AUTOSAR XML (schema 4-3-0)
package /BMW/Platform/Bs/SwcImplementations
  swc implementation Bs_Impl: behavior=Bs_IB
    code-descriptors:
      code Bs_Impl_Code: artifact-descriptors=autosar-engineering-object={short-label=Default, category=SWSRC}
package /BMW/Platform/Bs/SwComponentTypes
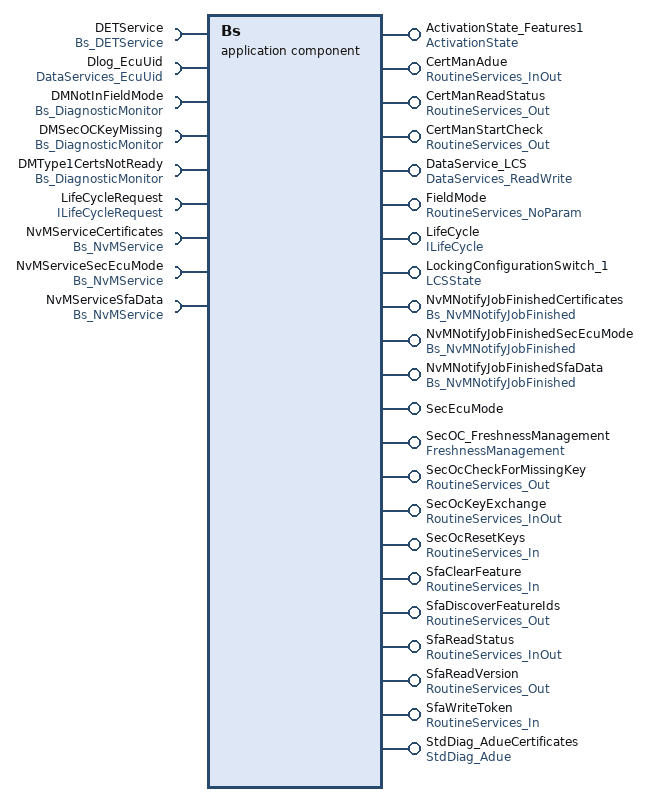
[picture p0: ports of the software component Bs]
  application sw component type Bs
    22 x provide port:
      ActivationState_Features1: nonqueued-sender-com-spec=data-element=IsActivated, provided-interface=ActivationState
      CertManAdue: server-com-spec{operation=Start, queue-length=1}, provided-interface=RoutineServices_InOut
      CertManReadStatus: server-com-spec{operation=Start, queue-length=1}, provided-interface=RoutineServices_Out
      CertManStartCheck: server-com-spec{operation=Start, queue-length=1}, provided-interface=RoutineServices_Out
      DataService_LCS: provided-interface=DataServices_ReadWrite
        provided-com-specs:
          operation=ConditionCheckRead, queue-length=1
          operation=ReadData, queue-length=1
          operation=ReadDataLength, queue-length=1
          operation=WriteData, queue-length=1
      FieldMode: server-com-spec{operation=Start, queue-length=1}, provided-interface=RoutineServices_NoParam
      LifeCycle: mode-switch-sender-com-spec{enhanced-mode-api=true, mode-group=Mode, queue-length=2}, provided-interface=ILifeCycle
      LockingConfigurationSwitch_1: nonqueued-sender-com-spec=data-element=value, provided-interface=LCSState
      NvMNotifyJobFinishedCertificates: server-com-spec{operation=JobFinished, queue-length=1}, provided-interface=Bs_NvMNotifyJobFinished
      NvMNotifyJobFinishedSecEcuMode: server-com-spec{operation=JobFinished, queue-length=1}, provided-interface=Bs_NvMNotifyJobFinished
      NvMNotifyJobFinishedSfaData: server-com-spec{operation=JobFinished, queue-length=1}, provided-interface=Bs_NvMNotifyJobFinished
      SecEcuMode: mode-switch-sender-com-spec{enhanced-mode-api=false, mode-group=Mode, queue-length=1}, provided-interface=SecEcuMode
      SecOC_FreshnessManagement: provided-interface=FreshnessManagement
        provided-com-specs:
          operation=GetRxFreshnessAuthData, queue-length=1
          operation=GetTxFreshnessTruncData, queue-length=1
          operation=SPduTxConfirmation, queue-length=1
      SecOcCheckForMissingKey: server-com-spec{operation=Start, queue-length=1}, provided-interface=RoutineServices_Out
      SecOcKeyExchange: server-com-spec{operation=Start, queue-length=1}, provided-interface=RoutineServices_InOut
      SecOcResetKeys: server-com-spec{operation=Start, queue-length=1}, provided-interface=RoutineServices_In
      SfaClearFeature: server-com-spec{operation=Start, queue-length=1}, provided-interface=RoutineServices_In
      SfaDiscoverFeatureIds: server-com-spec{operation=Start, queue-length=1}, provided-interface=RoutineServices_Out
      SfaReadStatus: server-com-spec{operation=Start, queue-length=1}, provided-interface=RoutineServices_InOut
      SfaReadVersion: server-com-spec{operation=Start, queue-length=1}, provided-interface=RoutineServices_Out
      SfaWriteToken: server-com-spec{operation=Start, queue-length=1}, provided-interface=RoutineServices_In
      StdDiag_AdueCertificates: provided-interface=StdDiag_Adue
        provided-com-specs:
          operation=CancelOperation, queue-length=1
          operation=Download, queue-length=1
          operation=DownloadPostprocess, queue-length=1
          operation=DownloadPreprocess, queue-length=1
          operation=RequestDownload, queue-length=1
          operation=RequestDownloadExit, queue-length=1
          operation=RequestUpload, queue-length=1
          operation=RequestUploadExit, queue-length=1
          operation=Upload, queue-length=1
          operation=UploadPostprocess, queue-length=1
          operation=UploadPreprocess, queue-length=1
    9 x require port:
      DETService: required-interface=Bs_DETService
      Dlog_EcuUid: required-interface=DataServices_EcuUid
      DMNotInFieldMode: required-interface=Bs_DiagnosticMonitor
      DMSecOCKeyMissing: required-interface=Bs_DiagnosticMonitor
      DMType1CertsNotReady: required-interface=Bs_DiagnosticMonitor
      LifeCycleRequest: nonqueued-receiver-com-spec{data-element=requestMode, filter=data-filter-type=ALWAYS, init-value=2}, required-interface=ILifeCycleRequest
      NvMServiceCertificates: required-interface=Bs_NvMService
      NvMServiceSecEcuMode: required-interface=Bs_NvMService
      NvMServiceSfaData: required-interface=Bs_NvMService
    behavior Bs_IB: data-type-mapping=BsTypeMappings, port-api-option{enable-take-address=true, error-handling=NO-TRANSFORMER-ERROR-HANDLING, indirect-api=false, port=ActivationState_Features1}
      11 x operation invoked event:
        oie_StdDiag_AdueCertificates_CancelOperation: start-on-event=Bs_AdueCertificatesCancel, operation=StdDiag_AdueCertificates.CancelOperation
        oie_StdDiag_AdueCertificates_Download: start-on-event=Bs_AdueCertificatesDownload, operation=StdDiag_AdueCertificates.Download
        oie_StdDiag_AdueCertificates_DownloadPostprocess: start-on-event=Bs_AdueCertificatesDownloadPostprocess, operation=StdDiag_AdueCertificates.DownloadPostprocess
        oie_StdDiag_AdueCertificates_DownloadPreprocess: start-on-event=Bs_AdueCertificatesDownloadPreprocess, operation=StdDiag_AdueCertificates.DownloadPreprocess
        oie_StdDiag_AdueCertificates_ReqeuestDownload: start-on-event=Bs_AdueCertificatesReqeuestDownload, operation=StdDiag_AdueCertificates.RequestDownload
        oie_StdDiag_AdueCertificates_RequestDownloadExit: start-on-event=Bs_AdueCertificatesRequestDownloadExit, operation=StdDiag_AdueCertificates.RequestDownloadExit
        oie_StdDiag_AdueCertificates_RequestUpload: start-on-event=Bs_AdueCertificatesRequestUpload, operation=StdDiag_AdueCertificates.RequestUpload
        oie_StdDiag_AdueCertificates_RequestUploadExit: start-on-event=Bs_AdueCertificatesRequestUploadExit, operation=StdDiag_AdueCertificates.RequestUploadExit
        oie_StdDiag_AdueCertificates_Upload: start-on-event=Bs_AdueCertificatesUpload, operation=StdDiag_AdueCertificates.Upload
        oie_StdDiag_AdueCertificates_UploadPostprocess: start-on-event=Bs_AdueCertificatesUploadPostprocess, operation=StdDiag_AdueCertificates.UploadPostprocess
        oie_StdDiag_AdueCertificates_UploadPreprocess: start-on-event=Bs_AdueCertificatesUploadPreprocess, operation=StdDiag_AdueCertificates.UploadPreprocess
      data received event dre_LifeCycleRequest: start-on-event=Bs_LifeCycleModeRequest, data=LifeCycleRequest.requestMode
      22 x operation invoked event:
        oie_NvMNotifyJobFinishedCertificates_JobFinished: start-on-event=Bs_NvMNotifyJobFinishedCertificates, operation=NvMNotifyJobFinishedCertificates.JobFinished
        oie_NvMNotifyJobFinishedSecEcuMode_JobFinished: start-on-event=Bs_NvMNotifyJobFinishedSecEcuMode, operation=NvMNotifyJobFinishedSecEcuMode.JobFinished
        oie_NvMNotifyJobFinishedSfaData_JobFinished: start-on-event=Bs_NvMNotifyJobFinishedSfaData, operation=NvMNotifyJobFinishedSfaData.JobFinished
        oie_SecOC_FreshnessManagement_GetRxFreshnessAuthData: start-on-event=Bs_SecOCFMGetRxFreshnessAuthData, operation=SecOC_FreshnessManagement.GetRxFreshnessAuthData
        oie_SecOC_FreshnessManagement_GetTxFreshnessTruncData: start-on-event=Bs_SecOCFMGetTxFreshnessTruncData, operation=SecOC_FreshnessManagement.GetTxFreshnessTruncData
        oie_SecOC_FreshnessManagement_SPduTxConfirmation: start-on-event=Bs_SecOCFMSPduTxConfirmation, operation=SecOC_FreshnessManagement.SPduTxConfirmation
        oie_DataService_LCS_ConditionCheckRead: start-on-event=Bs_UDSConditionCheckReadLCS, operation=DataService_LCS.ConditionCheckRead
        oie_DataService_LCS_ReadData: start-on-event=Bs_UDSReadDataByIdentifierLCS, operation=DataService_LCS.ReadData
        oie_DataService_LCS_ReadDataLength: start-on-event=Bs_UDSReadDataLengthLCS, operation=DataService_LCS.ReadDataLength
        oie_CertManAdue_Start: start-on-event=Bs_UDSRoutineControlStartCertManAdue, operation=CertManAdue.Start
        oie_CertManReadStatus_Start: start-on-event=Bs_UDSRoutineControlStartCertManReadStatus, operation=CertManReadStatus.Start
        oie_CertManStartCheck_Start: start-on-event=Bs_UDSRoutineControlStartCertManStartCheck, operation=CertManStartCheck.Start
        oie_FieldMode_Start: start-on-event=Bs_UDSRoutineControlStartFieldMode, operation=FieldMode.Start
        oie_SecOcCheckForMissingKey_Start: start-on-event=Bs_UDSRoutineControlStartSecOcCheckForMissingKey, operation=SecOcCheckForMissingKey.Start
        oie_SecOcKeyExchange_Start: start-on-event=Bs_UDSRoutineControlStartSecOcKeyExchange, operation=SecOcKeyExchange.Start
        oie_SecOcResetKeys_Start: start-on-event=Bs_UDSRoutineControlStartSecOcResetKeys, operation=SecOcResetKeys.Start
        oie_SfaClearFeature_Start: start-on-event=Bs_UDSRoutineControlStartSfaClearFeature, operation=SfaClearFeature.Start
        oie_SfaDiscoverFeatureIds_Start: start-on-event=Bs_UDSRoutineControlStartSfaDiscoverFeatureIds, operation=SfaDiscoverFeatureIds.Start
        oie_SfaReadStatus_Start: start-on-event=Bs_UDSRoutineControlStartSfaReadStatus, operation=SfaReadStatus.Start
        oie_SfaReadVersion_Start: start-on-event=Bs_UDSRoutineControlStartSfaReadVersion, operation=SfaReadVersion.Start
        oie_SfaWriteToken_Start: start-on-event=Bs_UDSRoutineControlStartSfaWriteToken, operation=SfaWriteToken.Start
        oie_DataService_LCS_WriteData: start-on-event=Bs_UDSWriteDataByIdentifierLCS, operation=DataService_LCS.WriteData
      34 x runnable:
        Bs_AdueCertificatesCancel
        Bs_AdueCertificatesDownload
        Bs_AdueCertificatesDownloadPostprocess
        Bs_AdueCertificatesDownloadPreprocess
        Bs_AdueCertificatesReqeuestDownload: symbol=Bs_AdueCertificates_ReqeuestDownload
        Bs_AdueCertificatesRequestDownloadExit
        Bs_AdueCertificatesRequestUpload
        Bs_AdueCertificatesRequestUploadExit
        Bs_AdueCertificatesUpload
        Bs_AdueCertificatesUploadPostprocess
        Bs_AdueCertificatesUploadPreprocess
          sync call scp_ReportError: operation=DETService.ReportError, timeout=0
        Bs_LifeCycleModeRequest: mode-access-point=LifeCycle.Mode
          data-read-access:
            access dra_requestMode: accessed-variable=LifeCycleRequest.requestMode
          mode switch point msp_proto_Bs_LifeCycle_0: mode-group=LifeCycle.Mode
          mode switch point msp_proto_SecEcuModeGroup_0: mode-group=SecEcuMode.Mode
          sync call scp_GetErrorStatus: operation=NvMServiceSecEcuMode.GetErrorStatus, timeout=0
          sync call scp_SetEventStatus: operation=DMNotInFieldMode.SetEventStatus, timeout=0
        Bs_NvMNotifyJobFinishedCertificates
        Bs_NvMNotifyJobFinishedSecEcuMode
        Bs_NvMNotifyJobFinishedSfaData
          data-send-points:
            access dsp_IsActivated: accessed-variable=ActivationState_Features1.IsActivated
          mode switch point msp_Mode_0: mode-group=SecEcuMode.Mode
          sync call scp_SetRamBlockStatus: operation=NvMServiceSecEcuMode.SetRamBlockStatus, timeout=0
        Bs_SecOCFMGetRxFreshnessAuthData
        Bs_SecOCFMGetTxFreshnessTruncData
        Bs_SecOCFMSPduTxConfirmation
        Bs_UDSConditionCheckReadLCS
        Bs_UDSReadDataByIdentifierLCS
        Bs_UDSReadDataLengthLCS
        Bs_UDSRoutineControlStartCertManAdue
        Bs_UDSRoutineControlStartCertManReadStatus
        Bs_UDSRoutineControlStartCertManStartCheck
        Bs_UDSRoutineControlStartFieldMode
          mode switch point msp_proto_SecEcuModeGroup_1: mode-group=SecEcuMode.Mode
          sync call scp_WriteBlock: operation=NvMServiceSecEcuMode.WriteBlock, timeout=0
        Bs_UDSRoutineControlStartSecOcCheckForMissingKey
        Bs_UDSRoutineControlStartSecOcKeyExchange
        Bs_UDSRoutineControlStartSecOcResetKeys
        Bs_UDSRoutineControlStartSfaClearFeature
        Bs_UDSRoutineControlStartSfaDiscoverFeatureIds
        Bs_UDSRoutineControlStartSfaReadStatus
        Bs_UDSRoutineControlStartSfaReadVersion
        Bs_UDSRoutineControlStartSfaWriteToken
          sync call scp_ReadData: operation=Dlog_EcuUid.ReadData, timeout=0
          sync call scp_WriteBlock: operation=NvMServiceSecEcuMode.WriteBlock, timeout=0
          sync call scp_WriteBlock1: operation=NvMServiceSfaData.WriteBlock, timeout=0
        Bs_UDSWriteDataByIdentifierLCS
      swc service dependency NvMCertificates
        assigned-ports:
          port-prototype=NvMServiceCertificates, role=NvMService
          port-prototype=NvMNotifyJobFinishedCertificates, role=NvMNotifyJobFinished
        service-needs:
          nv block needs NvMCertificates: restore-at-start=false, store-at-shutdown=false
      swc service dependency NvMSecEcuMode
        assigned-ports:
          port-prototype=NvMNotifyJobFinishedSecEcuMode, role=NvMNotifyJobFinished
          port-prototype=NvMServiceSecEcuMode, role=NvMService
        service-needs:
          nv block needs NvMSecEcuMode: restore-at-start=true, store-at-shutdown=false
      swc service dependency NvMSfaData
        assigned-ports:
          port-prototype=NvMNotifyJobFinishedSfaData, role=NvMNotifyJobFinished
          port-prototype=NvMServiceSfaData, role=NvMService
        service-needs:
          nv block needs NvMSfaData: restore-at-start=false, store-at-shutdown=false
